AUTOSAR XML (schema 4-0-3)
standard types defined: uint8, Boolean, UInt8
package /AUTOSAR_Platform/DataConstrs
  range DC_Boolean: raw 0..1
  range DC_UInt8: raw 0..255
package /DataTypes/Units
  unit NoUnit1: display-name=NoUnit, factor-si-to-unit=1, offset-si-to-unit=0
package /PATAC/Facility/DataTypes/Implementation
  compu method COMPU_Boolean: 0=FALSE, 1=TRUE
  unit NoUnit: factor-si-to-unit=1, offset-si-to-unit=0
package /PATAC/MSM/DataTypes
  parameter interface SeatMovCfg
    parameter data prototype Val: sw-calibration-access=READ-WRITE, type=UInt8
package /PATAC/MSM/DataTypes/ImplementationDataTypes
  impl type IfVeSMSeStNumConfig: category=VALUE, base-type=UInt8, sw-calibration-access=READ-ONLY, compu {0=SeatNum4Config, 1=SeatNum6Config, 2=SeatNum7Config, 3=SeatNum4PConfig, 4=SeatNumNDLBLow, 5=SeatNumNDLBHigh}, type-emitter=RTE
package /PATAC/MSM/ModeAdjust
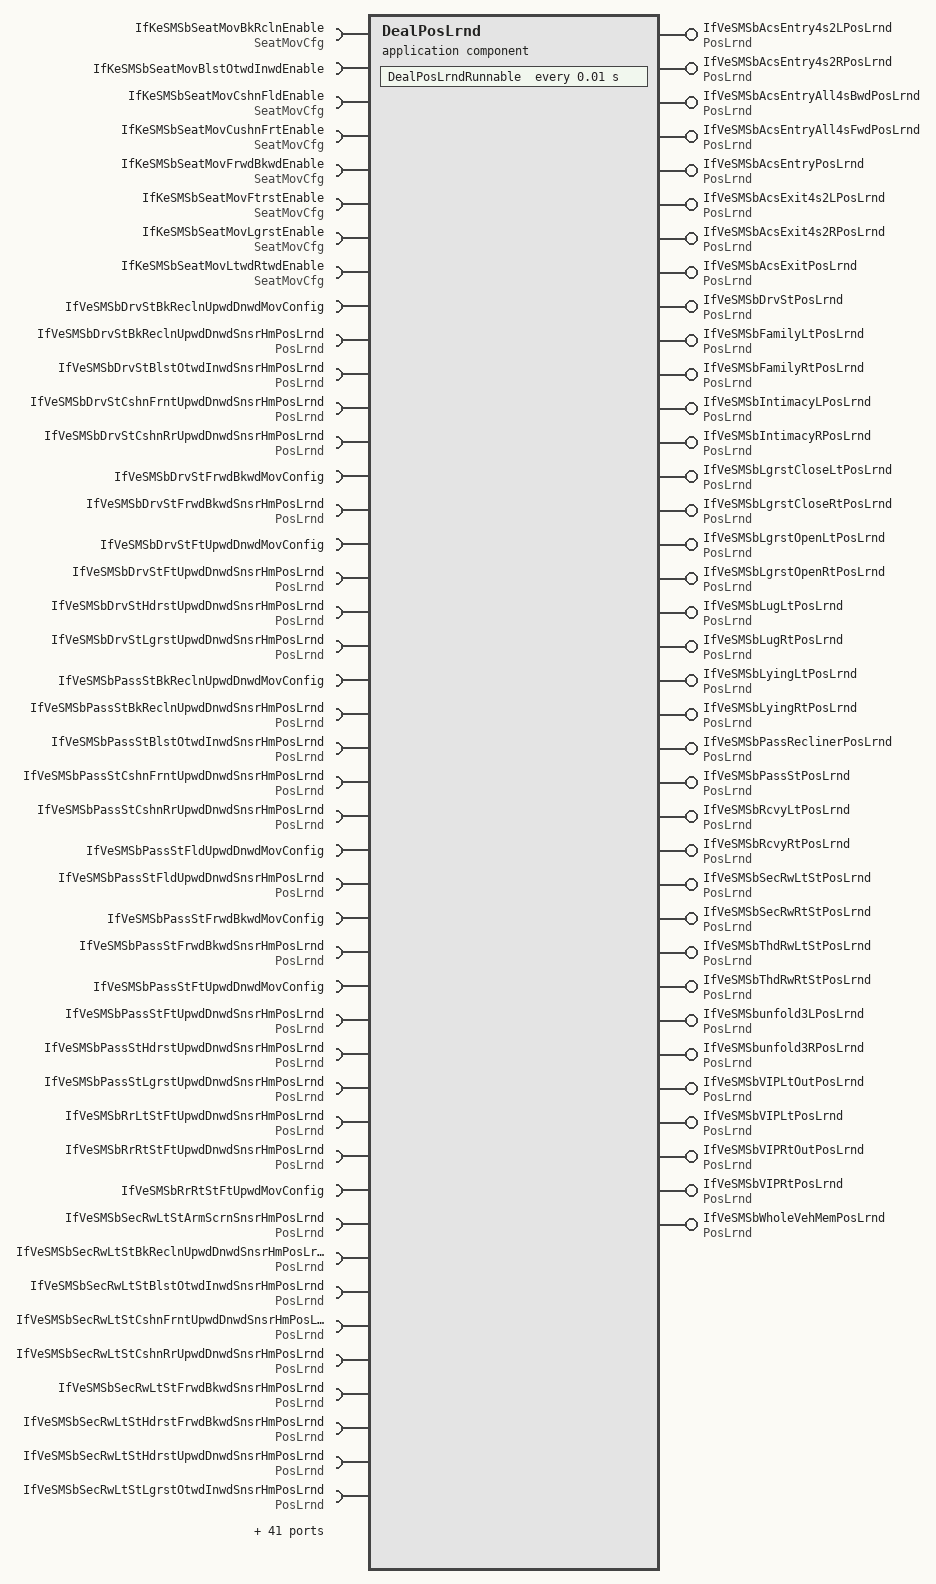
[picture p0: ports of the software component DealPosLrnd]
  application sw component type DealPosLrnd
    36 x provide port, all with provided-interface=PosLrnd:
      IfVeSMSbAcsEntry4s2LPosLrnd: nonqueued-sender-com-spec{data-element=PosLrnd/Val, init-value=ComSpecabdf31ce_0aa28dbd105e7722:0}
      IfVeSMSbAcsEntry4s2RPosLrnd: nonqueued-sender-com-spec{data-element=PosLrnd/Val, init-value=ComSpecbebab2a6_d57d53743de59fd8:0}
      IfVeSMSbAcsEntryAll4sBwdPosLrnd: nonqueued-sender-com-spec{data-element=PosLrnd/Val, init-value=ComSpec1f33e5f0_48e3e5bfe293747e:0}
      IfVeSMSbAcsEntryAll4sFwdPosLrnd: nonqueued-sender-com-spec{data-element=PosLrnd/Val, init-value=ComSpec8575c01c_8866df19a4d1ea5a:0}
      IfVeSMSbAcsEntryPosLrnd: nonqueued-sender-com-spec{data-element=PosLrnd/Val, init-value=ComSpecba88be38_c6662c14a1245f35:0}
      IfVeSMSbAcsExit4s2LPosLrnd: nonqueued-sender-com-spec{data-element=PosLrnd/Val, init-value=ComSpec75441356_2c90bf9fe5d4ec88:0}
      IfVeSMSbAcsExit4s2RPosLrnd: nonqueued-sender-com-spec{data-element=PosLrnd/Val, init-value=ComSpec5aa9d5d4_2652df4cdb16e296:0}
      IfVeSMSbAcsExitPosLrnd: nonqueued-sender-com-spec{data-element=PosLrnd/Val, init-value=ComSpec6958fb22_5a20b4a4a39e4540:0}
      IfVeSMSbDrvStPosLrnd: nonqueued-sender-com-spec{data-element=PosLrnd/Val, init-value=ComSpecd0c8a88e_2d8764284b6831af:0}
      IfVeSMSbFamilyLtPosLrnd: nonqueued-sender-com-spec{data-element=PosLrnd/Val, init-value=ComSpec2fd86fa3_af21533537f9ed89:0}
      IfVeSMSbFamilyRtPosLrnd: nonqueued-sender-com-spec{data-element=PosLrnd/Val, init-value=ComSpec31c45ede_9eb276ce8df428c1:0}
      IfVeSMSbIntimacyLPosLrnd: nonqueued-sender-com-spec{data-element=PosLrnd/Val, init-value=ComSpecc0e4499f_3dc4f8e2767069d4:0}
      IfVeSMSbIntimacyRPosLrnd: nonqueued-sender-com-spec{data-element=PosLrnd/Val, init-value=ComSpec9899e096_0af29dc66970b61a:0}
      IfVeSMSbLgrstCloseLtPosLrnd: nonqueued-sender-com-spec{data-element=PosLrnd/Val, init-value=ComSpec698e9cf8_7ef62ed63ccfe7a6:0}
      IfVeSMSbLgrstCloseRtPosLrnd: nonqueued-sender-com-spec{data-element=PosLrnd/Val, init-value=ComSpec9f47e44c_30ea026683db6687:0}
      IfVeSMSbLgrstOpenLtPosLrnd: nonqueued-sender-com-spec{data-element=PosLrnd/Val, init-value=ComSpec26086545_2d00fbaf93964c0d:0}
      IfVeSMSbLgrstOpenRtPosLrnd: nonqueued-sender-com-spec{data-element=PosLrnd/Val, init-value=ComSpec2c16e39c_98028d9f879eaf3f:0}
      IfVeSMSbLugLtPosLrnd: nonqueued-sender-com-spec{data-element=PosLrnd/Val, init-value=ComSpec2ff44ac0_01f975a39b138f42:0}
      IfVeSMSbLugRtPosLrnd: nonqueued-sender-com-spec{data-element=PosLrnd/Val, init-value=ComSpecac4d5b0f_f46de174eae7aae6:0}
      IfVeSMSbLyingLtPosLrnd: nonqueued-sender-com-spec{data-element=PosLrnd/Val, init-value=ComSpec0bac43fd_c2fcc5f39f2be185:0}
      IfVeSMSbLyingRtPosLrnd: nonqueued-sender-com-spec{data-element=PosLrnd/Val, init-value=ComSpecffd5c955_7d00e41611df8998:0}
      IfVeSMSbPassReclinerPosLrnd: nonqueued-sender-com-spec{data-element=PosLrnd/Val, init-value=ComSpeca8fd3ac5_f0f4218b6fbe65db:0}
      IfVeSMSbPassStPosLrnd: nonqueued-sender-com-spec{data-element=PosLrnd/Val, init-value=ComSpece744f9f4_3afc91c8a2cb44d6:0}
      IfVeSMSbRcvyLtPosLrnd: nonqueued-sender-com-spec{data-element=PosLrnd/Val, init-value=ComSpecf5a977f1_e969f57d430ca8ac:0}
      IfVeSMSbRcvyRtPosLrnd: nonqueued-sender-com-spec{data-element=PosLrnd/Val, init-value=ComSpecaefda2e9_ece0afee43df7913:0}
      IfVeSMSbSecRwLtStPosLrnd: nonqueued-sender-com-spec{data-element=PosLrnd/Val, init-value=ComSpecd297f461_295e44d8d73ddb7c:0}
      IfVeSMSbSecRwRtStPosLrnd: nonqueued-sender-com-spec{data-element=PosLrnd/Val, init-value=ComSpec89c23946_347ac06fd60363fe:0}
      IfVeSMSbThdRwLtStPosLrnd: nonqueued-sender-com-spec{data-element=PosLrnd/Val, init-value=ComSpecb759d0e7_9ff8847b71fc6df8:0}
      IfVeSMSbThdRwRtStPosLrnd: nonqueued-sender-com-spec{data-element=PosLrnd/Val, init-value=ComSpec2b8596d1_aefb3eb32932b5a5:0}
      IfVeSMSbunfold3LPosLrnd: nonqueued-sender-com-spec{data-element=PosLrnd/Val, init-value=ComSpec9ab302f2_cdb43c2dc6d5b431:0}
      IfVeSMSbunfold3RPosLrnd: nonqueued-sender-com-spec{data-element=PosLrnd/Val, init-value=ComSpecf542db7f_5e3dd878cada3ee9:0}
      IfVeSMSbVIPLtOutPosLrnd: nonqueued-sender-com-spec{data-element=PosLrnd/Val, init-value=ComSpecb31fa38c_de1d0ce1abe28e5d:0}
      IfVeSMSbVIPLtPosLrnd: nonqueued-sender-com-spec{data-element=PosLrnd/Val, init-value=ComSpec7490e171_a3d1cd20a84f6bb0:0}
      IfVeSMSbVIPRtOutPosLrnd: nonqueued-sender-com-spec{data-element=PosLrnd/Val, init-value=ComSpecfb5cf79d_2954e1e9c977b5cd:0}
      IfVeSMSbVIPRtPosLrnd: nonqueued-sender-com-spec{data-element=PosLrnd/Val, init-value=ComSpec19d905cb_68d0e46753e4c25c:0}
      IfVeSMSbWholeVehMemPosLrnd: nonqueued-sender-com-spec{data-element=PosLrnd/Val, init-value=0}
    85 x require port:
      IfKeSMSbSeatMovBkRclnEnable: parameter-require-com-spec{init-value=IfKeSMSbSeatMovBkRclnEnable_Val:1, parameter=SeatMovCfg/Val}, required-interface=SeatMovCfg
      IfKeSMSbSeatMovBlstOtwdInwdEnable: parameter-require-com-spec{init-value=0, parameter=IfKeSMSbSeatMovBlstOtwdInwdEnable/Val}, required-interface=IfKeSMSbSeatMovBlstOtwdInwdEnable
      IfKeSMSbSeatMovCshnFldEnable: parameter-require-com-spec{init-value=1, parameter=SeatMovCfg/Val}, required-interface=SeatMovCfg
      IfKeSMSbSeatMovCushnFrtEnable: parameter-require-com-spec{init-value=IfKeSMSbSeatMovCushnFrtEnable_Val:1, parameter=SeatMovCfg/Val}, required-interface=SeatMovCfg
      IfKeSMSbSeatMovFrwdBkwdEnable: parameter-require-com-spec{init-value=IfKeSMSbSeatMovFrwdBkwdEnable_Val:1, parameter=SeatMovCfg/Val}, required-interface=SeatMovCfg
      IfKeSMSbSeatMovFtrstEnable: parameter-require-com-spec{init-value=1, parameter=SeatMovCfg/Val}, required-interface=SeatMovCfg
      IfKeSMSbSeatMovLgrstEnable: parameter-require-com-spec{init-value=IfKeSMSbSeatMovLgrstEnable_Val:1, parameter=SeatMovCfg/Val}, required-interface=SeatMovCfg
      IfKeSMSbSeatMovLtwdRtwdEnable: parameter-require-com-spec{init-value=1, parameter=SeatMovCfg/Val}, required-interface=SeatMovCfg
      IfVeSMSbDrvStBkReclnUpwdDnwdMovConfig: nonqueued-receiver-com-spec{data-element=IfVeSMSbDrvStBkReclnUpwdDnwdMovConfig/Val, filter=data-filter-type=ALWAYS, init-value=0}, required-interface=IfVeSMSbDrvStBkReclnUpwdDnwdMovConfig
      IfVeSMSbDrvStBkReclnUpwdDnwdSnsrHmPosLrnd: nonqueued-receiver-com-spec{data-element=PosLrnd/Val, filter=data-filter-type=ALWAYS, init-value=0}, required-interface=PosLrnd
      IfVeSMSbDrvStBlstOtwdInwdSnsrHmPosLrnd: nonqueued-receiver-com-spec{data-element=PosLrnd/Val, filter=data-filter-type=ALWAYS, init-value=ComSpec3084a082_db76227ccdae0a36:0}, required-interface=PosLrnd
      IfVeSMSbDrvStCshnFrntUpwdDnwdSnsrHmPosLrnd: nonqueued-receiver-com-spec{data-element=PosLrnd/Val, filter=data-filter-type=ALWAYS, init-value=ComSpec3cee512f_b17149f6342f2849:0}, required-interface=PosLrnd
      IfVeSMSbDrvStCshnRrUpwdDnwdSnsrHmPosLrnd: nonqueued-receiver-com-spec{data-element=PosLrnd/Val, filter=data-filter-type=ALWAYS, init-value=ComSpecbf8554af_cfd752e05f39af91:0}, required-interface=PosLrnd
      IfVeSMSbDrvStFrwdBkwdMovConfig: nonqueued-receiver-com-spec{data-element=IfVeSMSbDrvStFrwdBkwdMovConfig/Val, filter=data-filter-type=ALWAYS, init-value=ComSpec7ee35b07_610fa9c4284c2144:0}, required-interface=IfVeSMSbDrvStFrwdBkwdMovConfig
      IfVeSMSbDrvStFrwdBkwdSnsrHmPosLrnd: nonqueued-receiver-com-spec{data-element=PosLrnd/Val, filter=data-filter-type=ALWAYS, init-value=ComSpec21eccef8_70b9bd1131b7f073:0}, required-interface=PosLrnd
      IfVeSMSbDrvStFtUpwdDnwdMovConfig: nonqueued-receiver-com-spec{data-element=IfVeSMSbDrvStFtUpwdDnwdMovConfig/Val, filter=data-filter-type=ALWAYS, init-value=ComSpec1e771549_b6446bd7fc80df71:0}, required-interface=IfVeSMSbDrvStFtUpwdDnwdMovConfig
      IfVeSMSbDrvStFtUpwdDnwdSnsrHmPosLrnd: nonqueued-receiver-com-spec{data-element=PosLrnd/Val, filter=data-filter-type=ALWAYS, init-value=ComSpec0b6fa6f3_d1f26da58ee080f1:0}, required-interface=PosLrnd
      IfVeSMSbDrvStHdrstUpwdDnwdSnsrHmPosLrnd: nonqueued-receiver-com-spec{data-element=PosLrnd/Val, filter=data-filter-type=ALWAYS, init-value=ComSpec9dc3090f_2809d18bc0e4cf03:0}, required-interface=PosLrnd
      IfVeSMSbDrvStLgrstUpwdDnwdSnsrHmPosLrnd: nonqueued-receiver-com-spec{data-element=PosLrnd/Val, filter=data-filter-type=ALWAYS, init-value=ComSpecb930b524_db13ad26fda24332:0}, required-interface=PosLrnd
      IfVeSMSbPassStBkReclnUpwdDnwdMovConfig: nonqueued-receiver-com-spec{data-element=IfVeSMSbPassStBkReclnUpwdDnwdMovConfig/Val, filter=data-filter-type=ALWAYS, init-value=ComSpecc8c3b54b_e3840d30cb39d22e:0}, required-interface=IfVeSMSbPassStBkReclnUpwdDnwdMovConfig
      IfVeSMSbPassStBkReclnUpwdDnwdSnsrHmPosLrnd: nonqueued-receiver-com-spec{data-element=PosLrnd/Val, filter=data-filter-type=ALWAYS, init-value=ComSpec9b8e0980_62cd939fc6e64187:0}, required-interface=PosLrnd
      IfVeSMSbPassStBlstOtwdInwdSnsrHmPosLrnd: nonqueued-receiver-com-spec{data-element=PosLrnd/Val, filter=data-filter-type=ALWAYS, init-value=ComSpece83c63b2_8ca4258808da21fb:0}, required-interface=PosLrnd
      IfVeSMSbPassStCshnFrntUpwdDnwdSnsrHmPosLrnd: nonqueued-receiver-com-spec{data-element=PosLrnd/Val, filter=data-filter-type=ALWAYS, init-value=ComSpecde0cf577_1bbd49a32cc7a127:0}, required-interface=PosLrnd
      IfVeSMSbPassStCshnRrUpwdDnwdSnsrHmPosLrnd: nonqueued-receiver-com-spec{data-element=PosLrnd/Val, filter=data-filter-type=ALWAYS, init-value=ComSpec145291fc_4c129db944402284:0}, required-interface=PosLrnd
      IfVeSMSbPassStFldUpwdDnwdMovConfig: nonqueued-receiver-com-spec{data-element=IfVeSMSbPassStFldUpwdDnwdMovConfig/Val, filter=data-filter-type=ALWAYS, init-value=ComSpec3098ee96_1f61c291f3c69997:0}, required-interface=IfVeSMSbPassStFldUpwdDnwdMovConfig
      IfVeSMSbPassStFldUpwdDnwdSnsrHmPosLrnd: nonqueued-receiver-com-spec{data-element=PosLrnd/Val, filter=data-filter-type=ALWAYS, init-value=ComSpec8e8b59b7_316d75544a9c8775:0}, required-interface=PosLrnd
      IfVeSMSbPassStFrwdBkwdMovConfig: nonqueued-receiver-com-spec{data-element=IfVeSMSbPassStFrwdBkwdMovConfig/Val, filter=data-filter-type=ALWAYS, init-value=ComSpec0beb6e97_32a3525da6d03a96:0}, required-interface=IfVeSMSbPassStFrwdBkwdMovConfig
      IfVeSMSbPassStFrwdBkwdSnsrHmPosLrnd: nonqueued-receiver-com-spec{data-element=PosLrnd/Val, filter=data-filter-type=ALWAYS, init-value=ComSpec8c050a65_23bd6b9d64255a13:0}, required-interface=PosLrnd
      IfVeSMSbPassStFtUpwdDnwdMovConfig: nonqueued-receiver-com-spec{data-element=IfVeSMSbPassStFtUpwdDnwdMovConfig/Val, filter=data-filter-type=ALWAYS, init-value=ComSpecd94628d7_bd5e76c2a2261e44:0}, required-interface=IfVeSMSbPassStFtUpwdDnwdMovConfig
      IfVeSMSbPassStFtUpwdDnwdSnsrHmPosLrnd: nonqueued-receiver-com-spec{data-element=PosLrnd/Val, filter=data-filter-type=ALWAYS, init-value=ComSpec99847cfa_89df882b6cf600b4:0}, required-interface=PosLrnd
      IfVeSMSbPassStHdrstUpwdDnwdSnsrHmPosLrnd: nonqueued-receiver-com-spec{data-element=PosLrnd/Val, filter=data-filter-type=ALWAYS, init-value=ComSpec55da3c2a_594f8970a4dee7a0:0}, required-interface=PosLrnd
      IfVeSMSbPassStLgrstUpwdDnwdSnsrHmPosLrnd: nonqueued-receiver-com-spec{data-element=PosLrnd/Val, filter=data-filter-type=ALWAYS, init-value=ComSpec8c91bf80_5c18029e7011b7be:0}, required-interface=PosLrnd
      IfVeSMSbRrLtStFtUpwdDnwdSnsrHmPosLrnd: nonqueued-receiver-com-spec{data-element=PosLrnd/Val, filter=data-filter-type=ALWAYS, init-value=ComSpece087d85c_5db7013193ed28bd:1}, required-interface=PosLrnd
      IfVeSMSbRrRtStFtUpwdDnwdSnsrHmPosLrnd: nonqueued-receiver-com-spec{data-element=PosLrnd/Val, filter=data-filter-type=ALWAYS, init-value=ComSpec57dd3712_7d060aa43f4d9c54:1}, required-interface=PosLrnd
      IfVeSMSbRrRtStFtUpwdMovConfig: nonqueued-receiver-com-spec{data-element=IfVeSMSbRrRtStFtUpwdMovConfig/Val, filter=data-filter-type=ALWAYS, init-value=ComSpecd84d9ece_91857c9b1e2be867:0}, required-interface=IfVeSMSbRrRtStFtUpwdMovConfig
      IfVeSMSbSecRwLtStArmScrnSnsrHmPosLrnd: nonqueued-receiver-com-spec{data-element=PosLrnd/Val, filter=data-filter-type=ALWAYS, init-value=ComSpecf414fc1c_111c671203028229:0}, required-interface=PosLrnd
      IfVeSMSbSecRwLtStBkReclnUpwdDnwdSnsrHmPosLrnd: nonqueued-receiver-com-spec{data-element=PosLrnd/Val, filter=data-filter-type=ALWAYS, init-value=ComSpecc6930155_f1a491cd831e8d12:0}, required-interface=PosLrnd
      IfVeSMSbSecRwLtStBlstOtwdInwdSnsrHmPosLrnd: nonqueued-receiver-com-spec{data-element=PosLrnd/Val, filter=data-filter-type=ALWAYS, init-value=ComSpec2aca9c33_a107e45b201e5079:0}, required-interface=PosLrnd
      IfVeSMSbSecRwLtStCshnFrntUpwdDnwdSnsrHmPosLrnd: nonqueued-receiver-com-spec{data-element=PosLrnd/Val, filter=data-filter-type=ALWAYS, init-value=ComSpecf8ac5bc2_9210e170e60c8e32:0}, required-interface=PosLrnd
      IfVeSMSbSecRwLtStCshnRrUpwdDnwdSnsrHmPosLrnd: nonqueued-receiver-com-spec{data-element=PosLrnd/Val, filter=data-filter-type=ALWAYS, init-value=ComSpecba0d7f82_fe3871ffd63bbae9:0}, required-interface=PosLrnd
      IfVeSMSbSecRwLtStFrwdBkwdSnsrHmPosLrnd: nonqueued-receiver-com-spec{data-element=PosLrnd/Val, filter=data-filter-type=ALWAYS, init-value=ComSpec7dc288c9_941f877d92d65496:0}, required-interface=PosLrnd
      IfVeSMSbSecRwLtStHdrstFrwdBkwdSnsrHmPosLrnd: nonqueued-receiver-com-spec{data-element=PosLrnd/Val, filter=data-filter-type=ALWAYS, init-value=ComSpec2d01bf7c_c190ff5345532df8:0}, required-interface=PosLrnd
      IfVeSMSbSecRwLtStHdrstUpwdDnwdSnsrHmPosLrnd: nonqueued-receiver-com-spec{data-element=PosLrnd/Val, filter=data-filter-type=ALWAYS, init-value=ComSpec13fe63bd_80179364c191fc0f:0}, required-interface=PosLrnd
      IfVeSMSbSecRwLtStLgrstOtwdInwdSnsrHmPosLrnd: nonqueued-receiver-com-spec{data-element=PosLrnd/Val, filter=data-filter-type=ALWAYS, init-value=ComSpec3f099ec9_78bafd179233774a:1}, required-interface=PosLrnd
      IfVeSMSbSecRwLtStLgrstUpwdDnwdSnsrHmPosLrnd: nonqueued-receiver-com-spec{data-element=PosLrnd/Val, filter=data-filter-type=ALWAYS, init-value=ComSpec24d65590_8cf4d7d3fd8adf4f:1}, required-interface=PosLrnd
      IfVeSMSbSecRwLtStLtwdRtwdSnsrHmPosLrnd: nonqueued-receiver-com-spec{data-element=PosLrnd/Val, filter=data-filter-type=ALWAYS, init-value=ComSpecaa5dbe68_10cddade5102de48:0}, required-interface=PosLrnd
      IfVeSMSbSecRwRtStArmScrnFrwdBkwdMovConfig: nonqueued-receiver-com-spec{data-element=SeatConfig/Val, filter=data-filter-type=ALWAYS, init-value=ComSpec4ec0f4ed_7d8e1ac8b5897151:0}, required-interface=SeatConfig
      IfVeSMSbSecRwRtStArmScrnSnsrHmPosLrnd: nonqueued-receiver-com-spec{data-element=PosLrnd/Val, filter=data-filter-type=ALWAYS, init-value=ComSpec140799d4_9f458d4c7f9a72e7:0}, required-interface=PosLrnd
      IfVeSMSbSecRwRtStBkReclnUpwdDnwdMovConfig: nonqueued-receiver-com-spec{data-element=IfVeSMSbSecRwRtStBkReclnUpwdDnwdMovConfig/Val, filter=data-filter-type=ALWAYS, init-value=ComSpec57af0ef2_8563b3918cb29a89:0}, required-interface=IfVeSMSbSecRwRtStBkReclnUpwdDnwdMovConfig
      IfVeSMSbSecRwRtStBkReclnUpwdDnwdSnsrHmPosLrnd: nonqueued-receiver-com-spec{data-element=PosLrnd/Val, filter=data-filter-type=ALWAYS, init-value=ComSpec13759f7a_e6c7b0e26e0cdf24:0}, required-interface=PosLrnd
      IfVeSMSbSecRwRtStBlstOtwdInwdMovConfig: nonqueued-receiver-com-spec{data-element=IfVeSMSbSecRwRtStBlstOtwdInwdMovConfig/Val, filter=data-filter-type=ALWAYS, init-value=ComSpec8e598f87_0ea883b641ac5683:0}, required-interface=IfVeSMSbSecRwRtStBlstOtwdInwdMovConfig
      IfVeSMSbSecRwRtStBlstOtwdInwdSnsrHmPosLrnd: nonqueued-receiver-com-spec{data-element=PosLrnd/Val, filter=data-filter-type=ALWAYS, init-value=ComSpec4febaa96_bc4e3b9a814c0c39:0}, required-interface=PosLrnd
      IfVeSMSbSecRwRtStCshnFrntUpwdDnwdMovConfig: nonqueued-receiver-com-spec{data-element=IfVeSMSbSecRwRtStCshnFrntUpwdDnwdMovConfig/Val, filter=data-filter-type=ALWAYS, init-value=ComSpec790404a5_8b539e84e62a2469:1}, required-interface=IfVeSMSbSecRwRtStCshnFrntUpwdDnwdMovConfig
      IfVeSMSbSecRwRtStCshnFrntUpwdDnwdSnsrHmPosLrnd: nonqueued-receiver-com-spec{data-element=PosLrnd/Val, filter=data-filter-type=ALWAYS, init-value=ComSpec21d7c00e_49cfe520e86da625:0}, required-interface=PosLrnd
      IfVeSMSbSecRwRtStCshnRrUpwdDnwdSnsrHmPosLrnd: nonqueued-receiver-com-spec{data-element=PosLrnd/Val, filter=data-filter-type=ALWAYS, init-value=ComSpec78bfa07a_8ce925b7e8ca7a72:0}, required-interface=PosLrnd
      IfVeSMSbSecRwRtStFrwdBkwdMovConfig: nonqueued-receiver-com-spec{data-element=IfVeSMSbSecRwRtStFrwdBkwdMovConfig/Val, filter=data-filter-type=ALWAYS, init-value=ComSpec54a64f52_acf1f9494dc4bbe4:0}, required-interface=IfVeSMSbSecRwRtStFrwdBkwdMovConfig
      IfVeSMSbSecRwRtStFrwdBkwdSnsrHmPosLrnd: nonqueued-receiver-com-spec{data-element=PosLrnd/Val, filter=data-filter-type=ALWAYS, init-value=ComSpeceaeed3b7_f439e83d2c5b7dbf:0}, required-interface=PosLrnd
      IfVeSMSbSecRwRtStHdrstFrwdBkwdSnsrHmPosLrnd: nonqueued-receiver-com-spec{data-element=PosLrnd/Val, filter=data-filter-type=ALWAYS, init-value=ComSpec7d0d412a_c8c3754ddcd2c170:0}, required-interface=PosLrnd
      IfVeSMSbSecRwRtStHdrstFrwdMovConfig: nonqueued-receiver-com-spec{data-element=IfVeSMSbSecRwRtStHdrstFrwdMovConfig/Val, filter=data-filter-type=ALWAYS, init-value=ComSpec6f6c11fe_4ae97b5f692981a1:0}, required-interface=IfVeSMSbSecRwRtStHdrstFrwdMovConfig
      IfVeSMSbSecRwRtStHdrstUpwdDnwdSnsrHmPosLrnd: nonqueued-receiver-com-spec{data-element=PosLrnd/Val, filter=data-filter-type=ALWAYS, init-value=ComSpec53d1c19f_18ba97a5a6fbb31a:0}, required-interface=PosLrnd
      IfVeSMSbSecRwRtStHdrstUpwdMovConfig: nonqueued-receiver-com-spec{data-element=IfVeSMSbSecRwRtStHdrstUpwdMovConfig/Val, filter=data-filter-type=ALWAYS, init-value=ComSpecc63a5565_312e656aa80c4092:0}, required-interface=IfVeSMSbSecRwRtStHdrstUpwdMovConfig
      IfVeSMSbSecRwRtStLgrstOtwdInwdMovConfig: nonqueued-receiver-com-spec{data-element=IfVeSMSbSecRwRtStLgrstOtwdInwdMovConfig/Val, filter=data-filter-type=ALWAYS, init-value=ComSpecf5643c92_efbb90b82071d8bb:0}, required-interface=IfVeSMSbSecRwRtStLgrstOtwdInwdMovConfig
      IfVeSMSbSecRwRtStLgrstOtwdInwdSnsrHmPosLrnd: nonqueued-receiver-com-spec{data-element=PosLrnd/Val, filter=data-filter-type=ALWAYS, init-value=ComSpec6b6e5bb3_907b1f39122b578f:0}, required-interface=PosLrnd
      IfVeSMSbSecRwRtStLgrstUpwdDnwdSnsrHmPosLrnd: nonqueued-receiver-com-spec{data-element=PosLrnd/Val, filter=data-filter-type=ALWAYS, init-value=ComSpec213043a5_cf6b6a5431d69c0e:0}, required-interface=PosLrnd
      IfVeSMSbSecRwRtStLgrstUpwdMovConfig: nonqueued-receiver-com-spec{data-element=IfVeSMSbSecRwRtStLgrstUpwdMovConfig/Val, filter=data-filter-type=ALWAYS, init-value=ComSpec8b6098c7_405cc335357b59d1:0}, required-interface=IfVeSMSbSecRwRtStLgrstUpwdMovConfig
      IfVeSMSbSecRwRtStLtwdRtwdMovConfig: nonqueued-receiver-com-spec{data-element=IfVeSMSbSecRwRtStLtwdRtwdMovConfig/Val, filter=data-filter-type=ALWAYS, init-value=ComSpeced4fdb85_aa66d7f7cf746235:0}, required-interface=IfVeSMSbSecRwRtStLtwdRtwdMovConfig
      IfVeSMSbSecRwRtStLtwdRtwdSnsrHmPosLrnd: nonqueued-receiver-com-spec{data-element=PosLrnd/Val, filter=data-filter-type=ALWAYS, init-value=ComSpec5c4b2fcb_012b8e6c0e678198:0}, required-interface=PosLrnd
      IfVeSMSbThdRwLtStBkReclnUpwdDnwdMovConfig: nonqueued-receiver-com-spec{data-element=IfVeSMSbThdRwLtStBkReclnUpwdDnwdMovConfig/Val, filter=data-filter-type=ALWAYS, init-value=ComSpece674df73_d7da512320936704:0}, required-interface=IfVeSMSbThdRwLtStBkReclnUpwdDnwdMovConfig
      IfVeSMSbThdRwLtStBkReclnUpwdDnwdSnsrHmPosLrnd: nonqueued-receiver-com-spec{data-element=PosLrnd/Val, filter=data-filter-type=ALWAYS, init-value=ComSpec5aa5fede_c21e70ad48901325:0}, required-interface=PosLrnd
      IfVeSMSbThdRwLtStCshnFldUpwdDnwdMovConfig: nonqueued-receiver-com-spec{data-element=IfVeSMSbThdRwLtStCshnFldUpwdDnwdMovConfig/Val, filter=data-filter-type=ALWAYS, init-value=ComSpec4a196d51_bac19b32a5a48937:0}, required-interface=IfVeSMSbThdRwLtStCshnFldUpwdDnwdMovConfig
      IfVeSMSbThdRwLtStCshnFldUpwdDnwdSnsrHmPosLrnd: nonqueued-receiver-com-spec{data-element=PosLrnd/Val, filter=data-filter-type=ALWAYS, init-value=ComSpec8dd51652_014a1f9b0e86ca6c:0}, required-interface=PosLrnd
      IfVeSMSbThdRwLtStFrwdBkwdMovConfig: nonqueued-receiver-com-spec{data-element=IfVeSMSbThdRwLtStFrwdBkwdMovConfig/Val, filter=data-filter-type=ALWAYS, init-value=ComSpec9ca336e1_02856a20da65a539:0}, required-interface=IfVeSMSbThdRwLtStFrwdBkwdMovConfig
      IfVeSMSbThdRwLtStFrwdBkwdSnsrHmPosLrnd: nonqueued-receiver-com-spec{data-element=PosLrnd/Val, filter=data-filter-type=ALWAYS, init-value=ComSpec30e4b8b9_977f7c18d1f50921:0}, required-interface=PosLrnd
      IfVeSMSbThdRwRtStBkReclnUpwdDnwdMovConfig: nonqueued-receiver-com-spec{data-element=IfVeSMSbThdRwRtStBkReclnUpwdDnwdMovConfig/Val, filter=data-filter-type=ALWAYS, init-value=ComSpecc2a5b17e_533441c395d9b0a5:0}, required-interface=IfVeSMSbThdRwRtStBkReclnUpwdDnwdMovConfig
      IfVeSMSbThdRwRtStBkReclnUpwdDnwdSnsrHmPosLrnd: nonqueued-receiver-com-spec{data-element=PosLrnd/Val, filter=data-filter-type=ALWAYS, init-value=ComSpeca22201f2_20559149945c969b:0}, required-interface=PosLrnd
      IfVeSMSbThdRwRtStCshnFldUpwdDnwdMovConfig: nonqueued-receiver-com-spec{data-element=IfVeSMSbThdRwRtStCshnFldUpwdDnwdMovConfig/Val, filter=data-filter-type=ALWAYS, init-value=ComSpec7997d541_e57e03c009d7cec1:0}, required-interface=IfVeSMSbThdRwRtStCshnFldUpwdDnwdMovConfig
      IfVeSMSbThdRwRtStCshnFldUpwdDnwdMovSnsrHmPosLrnd: nonqueued-receiver-com-spec{data-element=PosLrnd/Val, filter=data-filter-type=ALWAYS, init-value=ComSpec630f0182_c182ed397fd31ad1:0}, required-interface=PosLrnd
      IfVeSMSbThdRwRtStFrwdBkwdMovConfig: nonqueued-receiver-com-spec{data-element=IfVeSMSbThdRwRtStFrwdBkwdMovConfig/Val, filter=data-filter-type=ALWAYS, init-value=ComSpec4eff4904_bcc98e3a9d453de3:0}, required-interface=IfVeSMSbThdRwRtStFrwdBkwdMovConfig
      IfVeSMSbThdRwRtStFrwdBkwdSnsrHmPosLrnd: nonqueued-receiver-com-spec{data-element=PosLrnd/Val, filter=data-filter-type=ALWAYS, init-value=ComSpec7e92c5c0_4eb1f98f0ed7a013:0}, required-interface=PosLrnd
      IfVeSMSeStNumConfig: nonqueued-receiver-com-spec{data-element=IfVeSMSeStNumConfig/Val, filter=data-filter-type=ALWAYS, init-value=ComSpec74137809_3e64ae216b1a9e24:2}, required-interface=IfVeSMSeStNumConfig
      KeSMSbArmscreenMovEnable: parameter-require-com-spec{init-value=1, parameter=SeatMovCfg/Val}, required-interface=SeatMovCfg
      KeSMSbIgnorePosLrnd: parameter-require-com-spec{init-value=KeSMSbIgnorePosLrnd_Val:1, parameter=KeSMSbIgnorePosLrnd/Val}, required-interface=KeSMSbIgnorePosLrnd
      KeSMSbSeatMovHdFrwdBkwdEnable: parameter-require-com-spec{init-value=1, parameter=SeatMovCfg/Val}, required-interface=SeatMovCfg
      KeSMSbSeatMovHdUpwdDnwdEnable: parameter-require-com-spec{init-value=1, parameter=SeatMovCfg/Val}, required-interface=SeatMovCfg
      KeSMSbSeatMovLgrstExpdEnable: parameter-require-com-spec{init-value=KeSMSbSeatMovLgrstExpdEnable_Val:1, parameter=SeatMovCfg/Val}, required-interface=SeatMovCfg
    behavior DealPosLrnd_InternalBehavior
      timing event TMT_DealPosLrndRunnable: start-on-event=DealPosLrndRunnable, period=0.01
      runnable DealPosLrndRunnable: minimum-start-interval=0.01
        data-receive-point-by-arguments:
          72 x access:
            REC_IfVeSMSbDrvStBkReclnUpwdDnwdMovConfig_Val: accessed-variable=IfVeSMSbDrvStBkReclnUpwdDnwdMovConfig.Val
            REC_IfVeSMSbDrvStBkReclnUpwdDnwdSnsrHmPosLrnd_Val: accessed-variable=IfVeSMSbDrvStBkReclnUpwdDnwdSnsrHmPosLrnd.Val
            REC_IfVeSMSbDrvStBlstOtwdInwdSnsrHmPosLrnd_Val: accessed-variable=IfVeSMSbDrvStBlstOtwdInwdSnsrHmPosLrnd.Val
            REC_IfVeSMSbDrvStCshnFrntUpwdDnwdSnsrHmPosLrnd_Val: accessed-variable=IfVeSMSbDrvStCshnFrntUpwdDnwdSnsrHmPosLrnd.Val
            REC_IfVeSMSbDrvStCshnRrUpwdDnwdSnsrHmPosLrnd_Val: accessed-variable=IfVeSMSbDrvStCshnRrUpwdDnwdSnsrHmPosLrnd.Val
            REC_IfVeSMSbDrvStFrwdBkwdMovConfig_Val: accessed-variable=IfVeSMSbDrvStFrwdBkwdMovConfig.Val
            REC_IfVeSMSbDrvStFrwdBkwdSnsrHmPosLrnd_Val: accessed-variable=IfVeSMSbDrvStFrwdBkwdSnsrHmPosLrnd.Val
            REC_IfVeSMSbDrvStFtUpwdDnwdMovConfig_Val: accessed-variable=IfVeSMSbDrvStFtUpwdDnwdMovConfig.Val
            REC_IfVeSMSbDrvStFtUpwdDnwdSnsrHmPosLrnd_Val: accessed-variable=IfVeSMSbDrvStFtUpwdDnwdSnsrHmPosLrnd.Val
            REC_IfVeSMSbDrvStHdrstUpwdDnwdSnsrHmPosLrnd_Val: accessed-variable=IfVeSMSbDrvStHdrstUpwdDnwdSnsrHmPosLrnd.Val
            REC_IfVeSMSbDrvStLgrstUpwdDnwdSnsrHmPosLrnd_Val: accessed-variable=IfVeSMSbDrvStLgrstUpwdDnwdSnsrHmPosLrnd.Val
            REC_IfVeSMSbPassStBkReclnUpwdDnwdMovConfig_Val: accessed-variable=IfVeSMSbPassStBkReclnUpwdDnwdMovConfig.Val
            REC_IfVeSMSbPassStBkReclnUpwdDnwdSnsrHmPosLrnd_Val: accessed-variable=IfVeSMSbPassStBkReclnUpwdDnwdSnsrHmPosLrnd.Val
            REC_IfVeSMSbPassStBlstOtwdInwdSnsrHmPosLrnd_Val: accessed-variable=IfVeSMSbPassStBlstOtwdInwdSnsrHmPosLrnd.Val
            REC_IfVeSMSbPassStCshnFrntUpwdDnwdSnsrHmPosLrnd_Val: accessed-variable=IfVeSMSbPassStCshnFrntUpwdDnwdSnsrHmPosLrnd.Val
            REC_IfVeSMSbPassStCshnRrUpwdDnwdSnsrHmPosLrnd_Val: accessed-variable=IfVeSMSbPassStCshnRrUpwdDnwdSnsrHmPosLrnd.Val
            REC_IfVeSMSbPassStFldUpwdDnwdMovConfig_Val: accessed-variable=IfVeSMSbPassStFldUpwdDnwdMovConfig.Val
            REC_IfVeSMSbPassStFldUpwdDnwdSnsrHmPosLrnd_Val: accessed-variable=IfVeSMSbPassStFldUpwdDnwdSnsrHmPosLrnd.Val
            REC_IfVeSMSbPassStFrwdBkwdMovConfig_Val: accessed-variable=IfVeSMSbPassStFrwdBkwdMovConfig.Val
            REC_IfVeSMSbPassStFrwdBkwdSnsrHmPosLrnd_Val: accessed-variable=IfVeSMSbPassStFrwdBkwdSnsrHmPosLrnd.Val
            REC_IfVeSMSbPassStFtUpwdDnwdMovConfig_Val: accessed-variable=IfVeSMSbPassStFtUpwdDnwdMovConfig.Val
            REC_IfVeSMSbPassStFtUpwdDnwdSnsrHmPosLrnd_Val: accessed-variable=IfVeSMSbPassStFtUpwdDnwdSnsrHmPosLrnd.Val
            REC_IfVeSMSbPassStHdrstUpwdDnwdSnsrHmPosLrnd_Val: accessed-variable=IfVeSMSbPassStHdrstUpwdDnwdSnsrHmPosLrnd.Val
            REC_IfVeSMSbPassStLgrstUpwdDnwdSnsrHmPosLrnd_Val: accessed-variable=IfVeSMSbPassStLgrstUpwdDnwdSnsrHmPosLrnd.Val
            REC_IfVeSMSbRrLtStFtUpwdDnwdSnsrHmPosLrnd_Val: accessed-variable=IfVeSMSbRrLtStFtUpwdDnwdSnsrHmPosLrnd.Val
            REC_IfVeSMSbRrRtStFtUpwdDnwdSnsrHmPosLrnd_Val: accessed-variable=IfVeSMSbRrRtStFtUpwdDnwdSnsrHmPosLrnd.Val
            REC_IfVeSMSbRrRtStFtUpwdMovConfig_Val: accessed-variable=IfVeSMSbRrRtStFtUpwdMovConfig.Val
            REC_IfVeSMSbSecRwLtStArmScrnSnsrHmPosLrnd_Val: accessed-variable=IfVeSMSbSecRwLtStArmScrnSnsrHmPosLrnd.Val
            REC_IfVeSMSbSecRwLtStBkReclnUpwdDnwdSnsrHmPosLrnd_Val: accessed-variable=IfVeSMSbSecRwLtStBkReclnUpwdDnwdSnsrHmPosLrnd.Val
            REC_IfVeSMSbSecRwLtStBlstOtwdInwdSnsrHmPosLrnd_Val: accessed-variable=IfVeSMSbSecRwLtStBlstOtwdInwdSnsrHmPosLrnd.Val
            REC_IfVeSMSbSecRwLtStCshnFrntUpwdDnwdSnsrHmPosLrnd_Val: accessed-variable=IfVeSMSbSecRwLtStCshnFrntUpwdDnwdSnsrHmPosLrnd.Val
            REC_IfVeSMSbSecRwLtStCshnRrUpwdDnwdSnsrHmPosLrnd_Val: accessed-variable=IfVeSMSbSecRwLtStCshnRrUpwdDnwdSnsrHmPosLrnd.Val
            REC_IfVeSMSbSecRwLtStFrwdBkwdSnsrHmPosLrnd_Val: accessed-variable=IfVeSMSbSecRwLtStFrwdBkwdSnsrHmPosLrnd.Val
            REC_IfVeSMSbSecRwLtStHdrstFrwdBkwdSnsrHmPosLrnd_Val: accessed-variable=IfVeSMSbSecRwLtStHdrstFrwdBkwdSnsrHmPosLrnd.Val
            REC_IfVeSMSbSecRwLtStLgrstOtwdInwdSnsrHmPosLrnd_Val: accessed-variable=IfVeSMSbSecRwLtStLgrstOtwdInwdSnsrHmPosLrnd.Val
            REC_IfVeSMSbSecRwLtStLgrstUpwdDnwdSnsrHmPosLrnd_Val: accessed-variable=IfVeSMSbSecRwLtStLgrstUpwdDnwdSnsrHmPosLrnd.Val
            REC_IfVeSMSbSecRwLtStLtwdRtwdSnsrHmPosLrnd_Val: accessed-variable=IfVeSMSbSecRwLtStLtwdRtwdSnsrHmPosLrnd.Val
            REC_IfVeSMSbSecRwLtStUpwdDnwdSnsrHmPosLrnd_Val: accessed-variable=IfVeSMSbSecRwLtStHdrstUpwdDnwdSnsrHmPosLrnd.Val
            REC_IfVeSMSbSecRwRtStArmScrnFrwdBkwdMovConfig_Val: accessed-variable=IfVeSMSbSecRwRtStArmScrnFrwdBkwdMovConfig.Val
            REC_IfVeSMSbSecRwRtStArmScrnSnsrHmPosLrnd_Val: accessed-variable=IfVeSMSbSecRwRtStArmScrnSnsrHmPosLrnd.Val
            REC_IfVeSMSbSecRwRtStBkReclnUpwdDnwdMovConfig_Val: accessed-variable=IfVeSMSbSecRwRtStBkReclnUpwdDnwdMovConfig.Val
            REC_IfVeSMSbSecRwRtStBkReclnUpwdDnwdSnsrHmPosLrnd_Val: accessed-variable=IfVeSMSbSecRwRtStBkReclnUpwdDnwdSnsrHmPosLrnd.Val
            REC_IfVeSMSbSecRwRtStBlstOtwdInwdMovConfig_Val: accessed-variable=IfVeSMSbSecRwRtStBlstOtwdInwdMovConfig.Val
            REC_IfVeSMSbSecRwRtStBlstOtwdInwdSnsrHmPosLrnd_Val: accessed-variable=IfVeSMSbSecRwRtStBlstOtwdInwdSnsrHmPosLrnd.Val
            REC_IfVeSMSbSecRwRtStCshnFrntUpwdDnwdMovConfig_Val: accessed-variable=IfVeSMSbSecRwRtStCshnFrntUpwdDnwdMovConfig.Val
            REC_IfVeSMSbSecRwRtStCshnFrntUpwdDnwdSnsrHmPosLrnd_Val: accessed-variable=IfVeSMSbSecRwRtStCshnFrntUpwdDnwdSnsrHmPosLrnd.Val
            REC_IfVeSMSbSecRwRtStCshnRrUpwdDnwdSnsrHmPosLrnd_Val: accessed-variable=IfVeSMSbSecRwRtStCshnRrUpwdDnwdSnsrHmPosLrnd.Val
            REC_IfVeSMSbSecRwRtStFrwdBkwdMovConfig_Val: accessed-variable=IfVeSMSbSecRwRtStFrwdBkwdMovConfig.Val
            REC_IfVeSMSbSecRwRtStFrwdBkwdSnsrHmPosLrnd_Val: accessed-variable=IfVeSMSbSecRwRtStFrwdBkwdSnsrHmPosLrnd.Val
            REC_IfVeSMSbSecRwRtStHdrstFrwdBkwdSnsrHmPosLrnd_Val: accessed-variable=IfVeSMSbSecRwRtStHdrstFrwdBkwdSnsrHmPosLrnd.Val
            REC_IfVeSMSbSecRwRtStHdrstFrwdMovConfig_Val: accessed-variable=IfVeSMSbSecRwRtStHdrstFrwdMovConfig.Val
            REC_IfVeSMSbSecRwRtStHdrstUpwdMovConfig_Val: accessed-variable=IfVeSMSbSecRwRtStHdrstUpwdMovConfig.Val
            REC_IfVeSMSbSecRwRtStLgrstOtwdInwdMovConfig_Val: accessed-variable=IfVeSMSbSecRwRtStLgrstOtwdInwdMovConfig.Val
            REC_IfVeSMSbSecRwRtStLgrstOtwdInwdSnsrHmPosLrnd_Val: accessed-variable=IfVeSMSbSecRwRtStLgrstOtwdInwdSnsrHmPosLrnd.Val
            REC_IfVeSMSbSecRwRtStLgrstUpwdDnwdSnsrHmPosLrnd_Val: accessed-variable=IfVeSMSbSecRwRtStLgrstUpwdDnwdSnsrHmPosLrnd.Val
            REC_IfVeSMSbSecRwRtStLgrstUpwdMovConfig_Val: accessed-variable=IfVeSMSbSecRwRtStLgrstUpwdMovConfig.Val
            REC_IfVeSMSbSecRwRtStLtwdRtwdMovConfig_Val: accessed-variable=IfVeSMSbSecRwRtStLtwdRtwdMovConfig.Val
            REC_IfVeSMSbSecRwRtStLtwdRtwdSnsrHmPosLrnd_Val: accessed-variable=IfVeSMSbSecRwRtStLtwdRtwdSnsrHmPosLrnd.Val
            REC_IfVeSMSbSecRwRtStUpwdDnwdSnsrHmPosLrnd_Val: accessed-variable=IfVeSMSbSecRwRtStHdrstUpwdDnwdSnsrHmPosLrnd.Val
            REC_IfVeSMSbThdRwLtStBkReclnUpwdDnwdMovConfig_Val: accessed-variable=IfVeSMSbThdRwLtStBkReclnUpwdDnwdMovConfig.Val
            REC_IfVeSMSbThdRwLtStBkReclnUpwdDnwdSnsrHmPosLrnd_Val: accessed-variable=IfVeSMSbThdRwLtStBkReclnUpwdDnwdSnsrHmPosLrnd.Val
            REC_IfVeSMSbThdRwLtStCshnFldUpwdDnwdMovConfig_Val: accessed-variable=IfVeSMSbThdRwLtStCshnFldUpwdDnwdMovConfig.Val
            REC_IfVeSMSbThdRwLtStCshnFldUpwdDnwdSnsrHmPosLrnd_Val: accessed-variable=IfVeSMSbThdRwLtStCshnFldUpwdDnwdSnsrHmPosLrnd.Val
            REC_IfVeSMSbThdRwLtStFrwdBkwdMovConfig_Val: accessed-variable=IfVeSMSbThdRwLtStFrwdBkwdMovConfig.Val
            REC_IfVeSMSbThdRwLtStFrwdBkwdSnsrHmPosLrnd_Val: accessed-variable=IfVeSMSbThdRwLtStFrwdBkwdSnsrHmPosLrnd.Val
            REC_IfVeSMSbThdRwRtStBkReclnUpwdDnwdMovConfig_Val: accessed-variable=IfVeSMSbThdRwRtStBkReclnUpwdDnwdMovConfig.Val
            REC_IfVeSMSbThdRwRtStBkReclnUpwdDnwdSnsrHmPosLrnd_Val: accessed-variable=IfVeSMSbThdRwRtStBkReclnUpwdDnwdSnsrHmPosLrnd.Val
            REC_IfVeSMSbThdRwRtStBlstOtwdInwdSnsrHmPosLrnd_Val: accessed-variable=IfVeSMSbThdRwRtStCshnFldUpwdDnwdMovSnsrHmPosLrnd.Val
            REC_IfVeSMSbThdRwRtStCshnFldUpwdDnwdMovConfig_Val: accessed-variable=IfVeSMSbThdRwRtStCshnFldUpwdDnwdMovConfig.Val
            REC_IfVeSMSbThdRwRtStFrwdBkwdMovConfig_Val: accessed-variable=IfVeSMSbThdRwRtStFrwdBkwdMovConfig.Val
            REC_IfVeSMSbThdRwRtStFrwdBkwdSnsrHmPosLrnd_Val: accessed-variable=IfVeSMSbThdRwRtStFrwdBkwdSnsrHmPosLrnd.Val
            REC_IfVeSMSeStNumConfig_Val: accessed-variable=IfVeSMSeStNumConfig.Val
        data-send-points:
          36 x access:
            SEND_IfVeSMSbAcsEntry4s2LPosLrnd_Val: accessed-variable=IfVeSMSbAcsEntry4s2LPosLrnd.Val
            SEND_IfVeSMSbAcsEntry4s2RPosLrnd_Val: accessed-variable=IfVeSMSbAcsEntry4s2RPosLrnd.Val
            SEND_IfVeSMSbAcsEntryAll4sBwdPosLrnd_Val: accessed-variable=IfVeSMSbAcsEntryAll4sBwdPosLrnd.Val
            SEND_IfVeSMSbAcsEntryAll4sFwdPosLrnd_Val: accessed-variable=IfVeSMSbAcsEntryAll4sFwdPosLrnd.Val
            SEND_IfVeSMSbAcsExit4s2LPosLrnd_Val: accessed-variable=IfVeSMSbAcsExit4s2LPosLrnd.Val
            SEND_IfVeSMSbAcsExit4s2RPosLrnd_Val: accessed-variable=IfVeSMSbAcsExit4s2RPosLrnd.Val
            SEND_IfVeSMSbDrvStPosLrnd_Val: accessed-variable=IfVeSMSbAcsEntryPosLrnd.Val
            SEND_IfVeSMSbDrvStPosLrnd_Val_1: accessed-variable=IfVeSMSbDrvStPosLrnd.Val
            SEND_IfVeSMSbFamilyLtPosLrnd_Val: accessed-variable=IfVeSMSbFamilyLtPosLrnd.Val
            SEND_IfVeSMSbFamilyRtPosLrnd_Val: accessed-variable=IfVeSMSbFamilyRtPosLrnd.Val
            SEND_IfVeSMSbIntimacyPosLrnd_Val: accessed-variable=IfVeSMSbIntimacyLPosLrnd.Val
            SEND_IfVeSMSbIntimacyRPosLrnd_Val: accessed-variable=IfVeSMSbIntimacyRPosLrnd.Val
            SEND_IfVeSMSbLgrstCloseLtPosLrnd_Val: accessed-variable=IfVeSMSbLgrstCloseLtPosLrnd.Val
            SEND_IfVeSMSbLgrstCloseRtPosLrnd_Val: accessed-variable=IfVeSMSbLgrstCloseRtPosLrnd.Val
            SEND_IfVeSMSbLgrstOpenLtPosLrnd_Val: accessed-variable=IfVeSMSbLgrstOpenLtPosLrnd.Val
            SEND_IfVeSMSbLgrstOpenRtPosLrnd_Val: accessed-variable=IfVeSMSbLgrstOpenRtPosLrnd.Val
            SEND_IfVeSMSbLugLtPosLrnd_Val: accessed-variable=IfVeSMSbLugLtPosLrnd.Val
            SEND_IfVeSMSbLugRtPosLrnd_Val: accessed-variable=IfVeSMSbLugRtPosLrnd.Val
            SEND_IfVeSMSbLyingLtPosLrnd_Val: accessed-variable=IfVeSMSbLyingLtPosLrnd.Val
            SEND_IfVeSMSbLyingRtPosLrnd_Val: accessed-variable=IfVeSMSbLyingRtPosLrnd.Val
            SEND_IfVeSMSbPassReclinerPosLrnd_Val: accessed-variable=IfVeSMSbPassReclinerPosLrnd.Val
            SEND_IfVeSMSbPassStPosLrnd_Val: accessed-variable=IfVeSMSbAcsExitPosLrnd.Val
            SEND_IfVeSMSbPassStPosLrnd_Val_1: accessed-variable=IfVeSMSbPassStPosLrnd.Val
            SEND_IfVeSMSbSecRwLtPosLrnd_Val: accessed-variable=IfVeSMSbVIPLtPosLrnd.Val
            SEND_IfVeSMSbSecRwLtStPosLrnd_Val: accessed-variable=IfVeSMSbSecRwLtStPosLrnd.Val
            SEND_IfVeSMSbSecRwRtPosLrnd_Val: accessed-variable=IfVeSMSbVIPRtPosLrnd.Val
            SEND_IfVeSMSbSecRwRtStPosLrnd_Val: accessed-variable=IfVeSMSbSecRwRtStPosLrnd.Val
            SEND_IfVeSMSbThdRwLtPosLrnd_Val: accessed-variable=IfVeSMSbRcvyLtPosLrnd.Val
            SEND_IfVeSMSbThdRwLtStPosLrnd_Val: accessed-variable=IfVeSMSbThdRwLtStPosLrnd.Val
            SEND_IfVeSMSbThdRwRtPosLrnd_Val: accessed-variable=IfVeSMSbRcvyRtPosLrnd.Val
            SEND_IfVeSMSbThdRwRtStPosLrnd_Val: accessed-variable=IfVeSMSbThdRwRtStPosLrnd.Val
            SEND_IfVeSMSbunfold3LPosLrnd_Val: accessed-variable=IfVeSMSbunfold3LPosLrnd.Val
            SEND_IfVeSMSbunfold3RPosLrnd_Val: accessed-variable=IfVeSMSbunfold3RPosLrnd.Val
            SEND_IfVeSMSbVIPLtOutPosLrnd_Val: accessed-variable=IfVeSMSbVIPLtOutPosLrnd.Val
            SEND_IfVeSMSbVIPRtOutPosLrnd_Val: accessed-variable=IfVeSMSbVIPRtOutPosLrnd.Val
            SEND_IfVeSMSbWholeVehMemPosLrnd_Val: accessed-variable=IfVeSMSbWholeVehMemPosLrnd.Val
        13 x parameter access:
          PA_IfKeSMSbSeatMovBkRclnEnable_Val: accessed-parameter=IfKeSMSbSeatMovBkRclnEnable.Val
          PA_IfKeSMSbSeatMovBlstOtwdInwdEnable_Val: accessed-parameter=IfKeSMSbSeatMovBlstOtwdInwdEnable.Val
          PA_IfKeSMSbSeatMovCshnFldEnable_Val: accessed-parameter=IfKeSMSbSeatMovCshnFldEnable.Val
          PA_IfKeSMSbSeatMovCushnFrtEnable_Val: accessed-parameter=IfKeSMSbSeatMovCushnFrtEnable.Val
          PA_IfKeSMSbSeatMovFrwdBkwdEnable_Val: accessed-parameter=IfKeSMSbSeatMovFrwdBkwdEnable.Val
          PA_IfKeSMSbSeatMovFtrstEnable_Val: accessed-parameter=IfKeSMSbSeatMovFtrstEnable.Val
          PA_IfKeSMSbSeatMovLgrstEnable_Val: accessed-parameter=IfKeSMSbSeatMovLgrstEnable.Val
          PA_IfKeSMSbSeatMovLtwdRtwdEnable_Val: accessed-parameter=IfKeSMSbSeatMovLtwdRtwdEnable.Val
          PA_KeSMSbArmscreenMovEnable_Val: accessed-parameter=KeSMSbArmscreenMovEnable.Val
          PA_KeSMSbIgnorePosLrnd_Val: accessed-parameter=KeSMSbIgnorePosLrnd.Val
          PA_KeSMSbSeatMovHdFrwdBkwdEnable_Val: accessed-parameter=KeSMSbSeatMovHdFrwdBkwdEnable.Val
          PA_KeSMSbSeatMovHdUpwdDnwdEnable_Val: accessed-parameter=KeSMSbSeatMovHdUpwdDnwdEnable.Val
          PA_KeSMSbSeatMovLgrstExpdEnable_Val: accessed-parameter=KeSMSbSeatMovLgrstExpdEnable.Val
  swc implementation DealPosLrnd_Implementation: behavior=DealPosLrnd_InternalBehavior
    code-descriptors:
      code Default: artifact-descriptors=autosar-engineering-object={short-label=Default, category=SWSRC}
package /PATAC/MSM/ModeAdjust/CalPortInterface
  parameter interface KeSMSbIgnorePosLrnd
    parameter data prototype Val: sw-calibration-access=READ-WRITE, type=Boolean
package /PATAC/MSM/ModeAdjust/DataType
  impl type PosLrnd1: category=VALUE, base-type=Boolean, sw-calibration-access=READ-ONLY, type-emitter=RTE
package /PATAC/MSM/ModeAdjust/PortInterface
  7 x sender receiver interface:
    IfVeSMSbPassStFldUpwdDnwdMovConfig: invalidation-policy{data-element=IfVeSMSbPassStFldUpwdDnwdMovConfig/Val, handle-invalid=DONT-INVALIDATE}
      data Val: type=Boolean
    IfVeSMSbRrRtStFtUpwdMovConfig: invalidation-policy{data-element=IfVeSMSbRrRtStFtUpwdMovConfig/Val, handle-invalid=DONT-INVALIDATE}
      data Val: type=Boolean
    IfVeSMSbSecRwRtStBlstOtwdInwdMovConfig: invalidation-policy{data-element=IfVeSMSbSecRwRtStBlstOtwdInwdMovConfig/Val, handle-invalid=DONT-INVALIDATE}
      data Val: type=Boolean
    IfVeSMSbSecRwRtStHdrstFrwdMovConfig: invalidation-policy{data-element=IfVeSMSbSecRwRtStHdrstFrwdMovConfig/Val, handle-invalid=DONT-INVALIDATE}
      data Val: type=Boolean
    IfVeSMSbSecRwRtStLgrstOtwdInwdMovConfig: invalidation-policy{data-element=IfVeSMSbSecRwRtStLgrstOtwdInwdMovConfig/Val, handle-invalid=DONT-INVALIDATE}
      data Val: type=Boolean
    IfVeSMSeStNumConfig: invalidation-policy{data-element=IfVeSMSeStNumConfig/Val, handle-invalid=DONT-INVALIDATE}
      data Val: type=IfVeSMSeStNumConfig
    PosLrnd: invalidation-policy{data-element=PosLrnd/Val, handle-invalid=DONT-INVALIDATE}
      data Val: type=PosLrnd1
package /PATAC/MSM/PortInterfaces
  parameter interface IfKeSMSbSeatMovBlstOtwdInwdEnable
    parameter data prototype Val: sw-calibration-access=READ-WRITE, type=Boolean
  19 x sender receiver interface:
    IfVeSMSbDrvStBkReclnUpwdDnwdMovConfig: invalidation-policy{data-element=IfVeSMSbDrvStBkReclnUpwdDnwdMovConfig/Val, handle-invalid=DONT-INVALIDATE}
      data Val: type=Boolean
    IfVeSMSbDrvStFrwdBkwdMovConfig: invalidation-policy{data-element=IfVeSMSbDrvStFrwdBkwdMovConfig/Val, handle-invalid=DONT-INVALIDATE}
      data Val: type=Boolean
    IfVeSMSbDrvStFtUpwdDnwdMovConfig: invalidation-policy{data-element=IfVeSMSbDrvStFtUpwdDnwdMovConfig/Val, handle-invalid=DONT-INVALIDATE}
      data Val: type=Boolean
    IfVeSMSbPassStBkReclnUpwdDnwdMovConfig: invalidation-policy{data-element=IfVeSMSbPassStBkReclnUpwdDnwdMovConfig/Val, handle-invalid=DONT-INVALIDATE}
      data Val: type=Boolean
    IfVeSMSbPassStFrwdBkwdMovConfig: invalidation-policy{data-element=IfVeSMSbPassStFrwdBkwdMovConfig/Val, handle-invalid=DONT-INVALIDATE}
      data Val: type=Boolean
    IfVeSMSbPassStFtUpwdDnwdMovConfig: invalidation-policy{data-element=IfVeSMSbPassStFtUpwdDnwdMovConfig/Val, handle-invalid=DONT-INVALIDATE}
      data Val: type=Boolean
    IfVeSMSbSecRwRtStBkReclnUpwdDnwdMovConfig: invalidation-policy{data-element=IfVeSMSbSecRwRtStBkReclnUpwdDnwdMovConfig/Val, handle-invalid=DONT-INVALIDATE}
      data Val: type=Boolean
    IfVeSMSbSecRwRtStCshnFrntUpwdDnwdMovConfig: invalidation-policy{data-element=IfVeSMSbSecRwRtStCshnFrntUpwdDnwdMovConfig/Val, handle-invalid=DONT-INVALIDATE}
      data Val: type=Boolean
    IfVeSMSbSecRwRtStFrwdBkwdMovConfig: invalidation-policy{data-element=IfVeSMSbSecRwRtStFrwdBkwdMovConfig/Val, handle-invalid=DONT-INVALIDATE}
      data Val: type=Boolean
    IfVeSMSbSecRwRtStHdrstUpwdMovConfig: invalidation-policy{data-element=IfVeSMSbSecRwRtStHdrstUpwdMovConfig/Val, handle-invalid=DONT-INVALIDATE}
      data Val: type=Boolean
    IfVeSMSbSecRwRtStLgrstUpwdMovConfig: invalidation-policy{data-element=IfVeSMSbSecRwRtStLgrstUpwdMovConfig/Val, handle-invalid=DONT-INVALIDATE}
      data Val: type=Boolean
    IfVeSMSbSecRwRtStLtwdRtwdMovConfig: invalidation-policy{data-element=IfVeSMSbSecRwRtStLtwdRtwdMovConfig/Val, handle-invalid=DONT-INVALIDATE}
      data Val: type=Boolean
    IfVeSMSbThdRwLtStBkReclnUpwdDnwdMovConfig: invalidation-policy{data-element=IfVeSMSbThdRwLtStBkReclnUpwdDnwdMovConfig/Val, handle-invalid=DONT-INVALIDATE}
      data Val: type=Boolean
    IfVeSMSbThdRwLtStCshnFldUpwdDnwdMovConfig: invalidation-policy{data-element=IfVeSMSbThdRwLtStCshnFldUpwdDnwdMovConfig/Val, handle-invalid=DONT-INVALIDATE}
      data Val: type=Boolean
    IfVeSMSbThdRwLtStFrwdBkwdMovConfig: invalidation-policy{data-element=IfVeSMSbThdRwLtStFrwdBkwdMovConfig/Val, handle-invalid=DONT-INVALIDATE}
      data Val: type=Boolean
    IfVeSMSbThdRwRtStBkReclnUpwdDnwdMovConfig: invalidation-policy{data-element=IfVeSMSbThdRwRtStBkReclnUpwdDnwdMovConfig/Val, handle-invalid=DONT-INVALIDATE}
      data Val: type=Boolean
    IfVeSMSbThdRwRtStCshnFldUpwdDnwdMovConfig: invalidation-policy{data-element=IfVeSMSbThdRwRtStCshnFldUpwdDnwdMovConfig/Val, handle-invalid=DONT-INVALIDATE}
      data Val: type=Boolean
    IfVeSMSbThdRwRtStFrwdBkwdMovConfig: invalidation-policy{data-element=IfVeSMSbThdRwRtStFrwdBkwdMovConfig/Val, handle-invalid=DONT-INVALIDATE}
      data Val: type=Boolean
    SeatConfig: invalidation-policy{data-element=SeatConfig/Val, handle-invalid=DONT-INVALIDATE}
      data Val: type=Boolean
